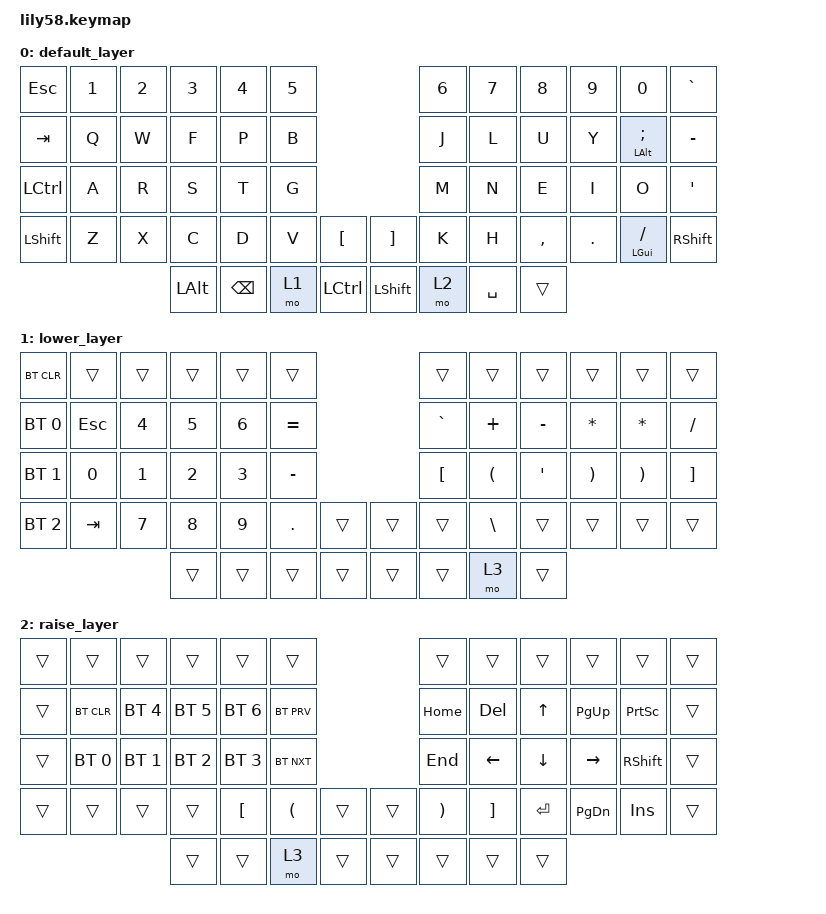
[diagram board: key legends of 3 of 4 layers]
/*
 * Copyright (c) 2020 The ZMK Contributors
 *
 * SPDX-License-Identifier: MIT
 */

#include <behaviors.dtsi>
#include <dt-bindings/zmk/keys.h>
#include <dt-bindings/zmk/bt.h>
#include <dt-bindings/zmk/ext_power.h>

/ {
	keymap {
		compatible = "zmk,keymap";

		default_layer {
// ------------------------------------------------------------------------------------------------------------
// |  ESC  |  1  |  2  |  3   |  4   |  5   |                   |  6   |  7    |  8    |  9   |   0   |   `   |
// |  TAB  |  Q  |  W  |  E   |  R   |  T   |                   |  Y   |  U    |  I    |  O   |   P   |   -   |
// |  CTRL |  A  |  S  |  D   |  F   |  G   |                   |  H   |  J    |  K    |  L   |   ;   |   '   |
// | SHIFT |  Z  |  X  |  C   |  V   |  B   |   "["  |  |  "]"  |  N   |  M    |  ,    |  .   |   /   | SHIFT |
//                     | ALT  | GUI  | LOWER|  SPACE |  | ENTER | RAISE| BSPC  | GUI   |
			bindings = <
&kp ESC   &kp N1 &kp N2 &kp N3   &kp N4   &kp N5                     	&kp N6 &kp N7    &kp N8    &kp N9  &kp N0	 &kp GRAVE
&kp TAB   &kp Q  &kp W  &kp F    &kp P    &kp B                      	&kp J  &kp L     &kp U     &kp Y   &mt LALT SEMI &kp MINUS
&kp LCTRL &kp A  &kp R  &kp S    &kp T    &kp G                      	&kp M  &kp N     &kp E     &kp I   &kp O	 &kp SQT
&kp LSHFT &kp Z  &kp X  &kp C    &kp D    &kp V  &kp LBKT   &kp RBKT	&kp K  &kp H	 &kp COMMA &kp DOT &mt LGUI FSLH &kp RSHFT
                        &kp LALT &kp BSPC &mo 1  &kp LCTRL  &kp LSHFT	&mo 2  &kp SPACE &trans
			>;

			sensor-bindings = <&inc_dec_kp C_VOL_UP C_VOL_DN>;
		};

		lower_layer {
// ------------------------------------------------------------------------------------------------------------
// | BTCLR | BT1 | BT2 |  BT3 |  BT4 |  BT5 |                   |      |       |       |      |       |       |
// |  F1   |  F2 |  F3 |  F4  |  F5  |  F6  |                   |  F7  |  F8   |  F9   |  F10 |  F11  |  F12  |
// |   `   |  !  |  @  |  #   |  $   |  %   |                   |  ^   |  &    |  *    |  (   |   )   |   ~   |
// |       |     |     |      |      |      |        |  |       |      |  _    |  +    |  {   |   }   |  "|"  |
//                     |      |      |      |        |  |       |      |       |       |
			bindings = <
&bt BT_CLR   &trans  &trans &trans      &trans &trans                    &trans    &trans   &trans    &trans   &trans   &trans
&bt BT_SEL 0 &kp ESC &kp N4 &kp N5	&kp N6 &kp EQUAL                 &kp GRAVE &kp PLUS &kp MINUS &kp STAR &kp STAR &kp SLASH
&bt BT_SEL 1 &kp N0  &kp N1 &kp N2	&kp N3 &kp MINUS                 &kp LBKT  &kp LPAR &kp SQT   &kp RPAR &kp RPAR &kp RBKT
&bt BT_SEL 2 &kp TAB &kp N7 &kp N8	&kp N9 &kp DOT   &trans   &trans &trans    &kp BSLH &trans    &trans   &trans   &trans
                         &trans &trans &trans    &trans   &trans &trans    &mo 3    &trans
			>;

			sensor-bindings = <&inc_dec_kp C_VOL_UP C_VOL_DN>;
		};

		raise_layer {
// ------------------------------------------------------------------------------------------------------------
// |       |     |     |      |      |      |                   |      |       |       |      |       |       |
// |   `   |  1  |  2  |  3   |  4   |  5   |                   |  6   |   7   |   8   |  9   |   0   |       |
// |   F1  |  F2 |  F3 |  F4  |  F5  |  F6  |                   |      |   <-  |   v   |  ^   |  ->   |       |
// |   F7  |  F8 |  F9 |  F10 |  F11 |  F12 |        |  |       |  +   |   -   |   =   |  [   |   ]   |   \   |
//                     |      |      |      |        |  |       |      |       |       |
			bindings = <
&trans  &trans      &trans       &trans       &trans       &trans                     &trans   &trans   &trans   &trans    &trans    &trans
&trans &bt BT_CLR   &bt BT_SEL 4 &bt BT_SEL 5 &bt BT_SEL 6 &bt BT_PRV                 &kp HOME &kp DEL  &kp UP   &kp PG_UP &kp PSCRN &trans
&trans &bt BT_SEL 0 &bt BT_SEL 1 &bt BT_SEL 2 &bt BT_SEL 3 &bt BT_NXT                 &kp END  &kp LEFT &kp DOWN &kp RIGHT &kp RSHFT &trans
&trans &trans       &trans       &trans       &kp LBKT     &kp LPAR   &trans   &trans &kp RPAR &kp RBKT &kp RET  &kp PG_DN &kp INS   &trans
                                 &trans       &trans       &mo 3      &trans   &trans &trans   &trans   &trans
			>;

			sensor-bindings = <&inc_dec_kp C_VOL_UP C_VOL_DN>;
		};
		
                sys_layer {
// -----------------------------------------------------------------------------------------
// |     |     |     |     |     |   |  A  |  7  |  8  |  9  |  D  |
// |     |     |     |     |     |   |  B  |  4  |  5  |  6  |  E  |
// |     |     |     |     |     |   |  C  |  1  |  2  |  3  |  F  |
//             |     |     |     |   |  0  |  .  |     |
                        bindings = <
   &trans  &kp F4 &kp F5 &kp F6 &trans    &kp CAPS &kp PSCRN &kp SLCK &kp PAUSE_BREAK &kp LNLCK
   &kp F10 &kp F1 &kp F2 &kp F3 &kp F11   &trans   &trans    &trans   &trans          &trans
   &trans  &kp F7 &kp F8 &kp F9 &kp F12   &trans   &trans    &trans   &trans          &trans
                  &trans &trans &trans    &trans   &trans    &trans
                        >;
			
			sensor-bindings = <&inc_dec_kp C_VOL_UP C_VOL_DN>;
                };
	};
};
